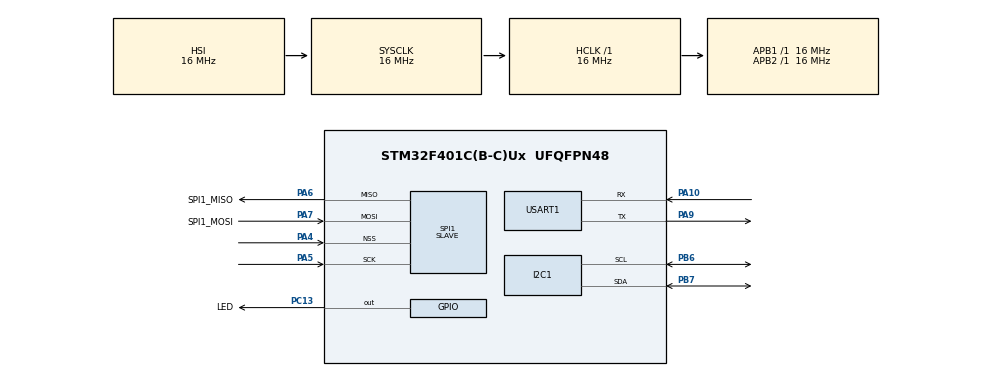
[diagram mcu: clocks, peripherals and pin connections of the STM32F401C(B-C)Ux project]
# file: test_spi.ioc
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Mcu.Family=STM32F4
Mcu.Name=STM32F401C(B-C)Ux
Mcu.Package=UFQFPN48
NVIC.PriorityGroup=NVIC_PRIORITYGROUP_4
NVIC.SPI1_IRQn=true\:0\:0\:false\:false\:true\:true\:true\:true
NVIC.TIM2_IRQn=true\:0\:0\:false\:false\:true\:true\:true\:true
NVIC.USART1_IRQn=true\:0\:0\:false\:false\:true\:true\:true\:true
PA10.Mode=Asynchronous
PA10.Signal=USART1_RX
PA4.Mode=NSS_Signal_Hard_Input
PA4.Signal=SPI1_NSS
PA5.Mode=Full_Duplex_Slave
PA5.Signal=SPI1_SCK
PA6.GPIO_Label=SPI1_MISO
PA6.Mode=Full_Duplex_Slave
PA6.Signal=SPI1_MISO
PA7.GPIO_Label=SPI1_MOSI
PA7.Mode=Full_Duplex_Slave
PA7.Signal=SPI1_MOSI
PA9.Mode=Asynchronous
PA9.Signal=USART1_TX
PB6.Mode=I2C
PB6.Signal=I2C1_SCL
PB7.Mode=I2C
PB7.Signal=I2C1_SDA
PC13-ANTI_TAMP.GPIO_Label=LED
PC13-ANTI_TAMP.GPIO_ModeDefaultOutputPP=GPIO_MODE_OUTPUT_PP
PC13-ANTI_TAMP.GPIO_PuPd=GPIO_NOPULL
PC13-ANTI_TAMP.Signal=GPIO_Output
PH0\ -\ OSC_IN.Mode=HSE-External-Oscillator
PH0\ -\ OSC_IN.Signal=RCC_OSC_IN
PH1\ -\ OSC_OUT.Mode=HSE-External-Oscillator
PH1\ -\ OSC_OUT.Signal=RCC_OSC_OUT
ProjectManager.HeapSize=0x200
ProjectManager.StackSize=0x400
ProjectManager.TargetToolchain=STM32CubeIDE
RCC.AHBFreq_Value=16000000
RCC.APB1Freq_Value=16000000
RCC.APB2Freq_Value=16000000
RCC.CortexFreq_Value=16000000
RCC.HSE_VALUE=25000000
RCC.HSI_VALUE=16000000
RCC.LSE_VALUE=32768
RCC.SYSCLKFreq_VALUE=16000000
RCC.VCOOutputFreq_Value=192000000
SPI1.CLKPhase=SPI_PHASE_1EDGE
SPI1.CLKPolarity=SPI_POLARITY_LOW
SPI1.CRCCalculation=SPI_CRCCALCULATION_DISABLE
SPI1.Direction=SPI_DIRECTION_2LINES
SPI1.FirstBit=SPI_FIRSTBIT_MSB
SPI1.Mode=SPI_MODE_SLAVE
SPI1.VirtualNSS=VM_NSSHARD
SPI1.VirtualType=VM_SLAVE
TIM2.AutoReloadPreload=TIM_AUTORELOAD_PRELOAD_ENABLE
TIM2.Period=16000
TIM2.Prescaler=1000
USART1.Parity=PARITY_ODD
USART1.VirtualMode=VM_ASYNC
USART1.WordLength=WORDLENGTH_9B
VP_TIM2_VS_ClockSourceINT.Mode=Internal
board=custom

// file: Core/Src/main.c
/* USER CODE BEGIN Header */
/**
  ******************************************************************************
  * @file           : main.c
  * @brief          : Main program body
  ******************************************************************************
  * @attention
  *
  * Copyright (c) 2022 STMicroelectronics.
  * All rights reserved.
  *
  * This software is licensed under terms that can be found in the LICENSE file
  * in the root directory of this software component.
  * If no LICENSE file comes with this software, it is provided AS-IS.
  *
  ******************************************************************************
  */
/* USER CODE END Header */
#include "main.h"

/* USER CODE BEGIN Includes */
#include "maincode.h"
/* USER CODE END Includes */

 I2C_HandleTypeDef hi2c1;

SPI_HandleTypeDef hspi1;

TIM_HandleTypeDef htim2;

UART_HandleTypeDef huart1;

void SystemClock_Config(void);
static void MX_GPIO_Init(void);
static void MX_SPI1_Init(void);
static void MX_USART1_UART_Init(void);
static void MX_I2C1_Init(void);
static void MX_TIM2_Init(void);

int main(void)
{

  /* MCU Configuration--------------------------------------------------------*/

  /* Reset of all peripherals, Initializes the Flash interface and the Systick. */
  HAL_Init();

  /* Configure the system clock */
  SystemClock_Config();

  /* Initialize all configured peripherals */
  MX_GPIO_Init();
  MX_SPI1_Init();
  MX_USART1_UART_Init();
  MX_I2C1_Init();
  MX_TIM2_Init();
  /* USER CODE BEGIN 2 */
  HAL_GPIO_WritePin(LED_GPIO_Port, LED_Pin, 1);
  lcd_start();
  HAL_TIM_Base_Start_IT(&htim2);
  /* USER CODE END 2 */

  /* Infinite loop */
  while (1)
  {

    /* USER CODE BEGIN 3 */
	mainloop();
  }
  /* USER CODE END 3 */
}

void SystemClock_Config(void)
{
  RCC_OscInitTypeDef RCC_OscInitStruct = {0};
  RCC_ClkInitTypeDef RCC_ClkInitStruct = {0};

  /** Configure the main internal regulator output voltage
  */
  __HAL_RCC_PWR_CLK_ENABLE();
  __HAL_PWR_VOLTAGESCALING_CONFIG(PWR_REGULATOR_VOLTAGE_SCALE2);

  /** Initializes the RCC Oscillators according to the specified parameters
  * in the RCC_OscInitTypeDef structure.
  */
  RCC_OscInitStruct.OscillatorType = RCC_OSCILLATORTYPE_HSI;
  RCC_OscInitStruct.HSIState = RCC_HSI_ON;
  RCC_OscInitStruct.HSICalibrationValue = RCC_HSICALIBRATION_DEFAULT;
  RCC_OscInitStruct.PLL.PLLState = RCC_PLL_NONE;
  if (HAL_RCC_OscConfig(&RCC_OscInitStruct) != HAL_OK)
  {
    Error_Handler();
  }

  /** Initializes the CPU, AHB and APB buses clocks
  */
  RCC_ClkInitStruct.ClockType = RCC_CLOCKTYPE_HCLK|RCC_CLOCKTYPE_SYSCLK
                              |RCC_CLOCKTYPE_PCLK1|RCC_CLOCKTYPE_PCLK2;
  RCC_ClkInitStruct.SYSCLKSource = RCC_SYSCLKSOURCE_HSI;
  RCC_ClkInitStruct.AHBCLKDivider = RCC_SYSCLK_DIV1;
  RCC_ClkInitStruct.APB1CLKDivider = RCC_HCLK_DIV1;
  RCC_ClkInitStruct.APB2CLKDivider = RCC_HCLK_DIV1;

  if (HAL_RCC_ClockConfig(&RCC_ClkInitStruct, FLASH_LATENCY_0) != HAL_OK)
  {
    Error_Handler();
  }
}

static void MX_I2C1_Init(void)
{

  hi2c1.Instance = I2C1;
  hi2c1.Init.ClockSpeed = 100000;
  hi2c1.Init.DutyCycle = I2C_DUTYCYCLE_2;
  hi2c1.Init.OwnAddress1 = 0;
  hi2c1.Init.AddressingMode = I2C_ADDRESSINGMODE_7BIT;
  hi2c1.Init.DualAddressMode = I2C_DUALADDRESS_DISABLE;
  hi2c1.Init.OwnAddress2 = 0;
  hi2c1.Init.GeneralCallMode = I2C_GENERALCALL_DISABLE;
  hi2c1.Init.NoStretchMode = I2C_NOSTRETCH_DISABLE;
  if (HAL_I2C_Init(&hi2c1) != HAL_OK)
  {
    Error_Handler();
  }

}

static void MX_SPI1_Init(void)
{

  /* SPI1 parameter configuration*/
  hspi1.Instance = SPI1;
  hspi1.Init.Mode = SPI_MODE_SLAVE;
  hspi1.Init.Direction = SPI_DIRECTION_2LINES;
  hspi1.Init.DataSize = SPI_DATASIZE_8BIT;
  hspi1.Init.CLKPolarity = SPI_POLARITY_LOW;
  hspi1.Init.CLKPhase = SPI_PHASE_1EDGE;
  hspi1.Init.NSS = SPI_NSS_HARD_INPUT;
  hspi1.Init.FirstBit = SPI_FIRSTBIT_MSB;
  hspi1.Init.TIMode = SPI_TIMODE_DISABLE;
  hspi1.Init.CRCCalculation = SPI_CRCCALCULATION_DISABLE;
  hspi1.Init.CRCPolynomial = 10;
  if (HAL_SPI_Init(&hspi1) != HAL_OK)
  {
    Error_Handler();
  }
  /* USER CODE BEGIN SPI1_Init 2 */
  NVIC_SetPriority(SPI1_IRQn, NVIC_EncodePriority(NVIC_GetPriorityGrouping(), 0, 0));
  NVIC_EnableIRQ(SPI1_IRQn);
  /* USER CODE END SPI1_Init 2 */

}

static void MX_TIM2_Init(void)
{

  TIM_ClockConfigTypeDef sClockSourceConfig = {0};
  TIM_MasterConfigTypeDef sMasterConfig = {0};

  htim2.Instance = TIM2;
  htim2.Init.Prescaler = 1000;
  htim2.Init.CounterMode = TIM_COUNTERMODE_UP;
  htim2.Init.Period = 16000;
  htim2.Init.ClockDivision = TIM_CLOCKDIVISION_DIV1;
  htim2.Init.AutoReloadPreload = TIM_AUTORELOAD_PRELOAD_ENABLE;
  if (HAL_TIM_Base_Init(&htim2) != HAL_OK)
  {
    Error_Handler();
  }
  sClockSourceConfig.ClockSource = TIM_CLOCKSOURCE_INTERNAL;
  if (HAL_TIM_ConfigClockSource(&htim2, &sClockSourceConfig) != HAL_OK)
  {
    Error_Handler();
  }
  sMasterConfig.MasterOutputTrigger = TIM_TRGO_RESET;
  sMasterConfig.MasterSlaveMode = TIM_MASTERSLAVEMODE_DISABLE;
  if (HAL_TIMEx_MasterConfigSynchronization(&htim2, &sMasterConfig) != HAL_OK)
  {
    Error_Handler();
  }

}

static void MX_USART1_UART_Init(void)
{

  huart1.Instance = USART1;
  huart1.Init.BaudRate = 115200;
  huart1.Init.WordLength = UART_WORDLENGTH_9B;
  huart1.Init.StopBits = UART_STOPBITS_1;
  huart1.Init.Parity = UART_PARITY_ODD;
  huart1.Init.Mode = UART_MODE_TX_RX;
  huart1.Init.HwFlowCtl = UART_HWCONTROL_NONE;
  huart1.Init.OverSampling = UART_OVERSAMPLING_16;
  if (HAL_UART_Init(&huart1) != HAL_OK)
  {
    Error_Handler();
  }
  /* USER CODE BEGIN USART1_Init 2 */
  NVIC_SetPriority(USART1_IRQn, NVIC_EncodePriority(NVIC_GetPriorityGrouping(), 0, 0));
  NVIC_EnableIRQ(USART1_IRQn);
  /* USER CODE END USART1_Init 2 */

}

static void MX_GPIO_Init(void)
{
  GPIO_InitTypeDef GPIO_InitStruct = {0};

  /* GPIO Ports Clock Enable */
  __HAL_RCC_GPIOC_CLK_ENABLE();
  __HAL_RCC_GPIOH_CLK_ENABLE();
  __HAL_RCC_GPIOA_CLK_ENABLE();
  __HAL_RCC_GPIOB_CLK_ENABLE();

  /*Configure GPIO pin Output Level */
  HAL_GPIO_WritePin(LED_GPIO_Port, LED_Pin, GPIO_PIN_RESET);

  /*Configure GPIO pin : LED_Pin */
  GPIO_InitStruct.Pin = LED_Pin;
  GPIO_InitStruct.Mode = GPIO_MODE_OUTPUT_PP;
  GPIO_InitStruct.Pull = GPIO_NOPULL;
  GPIO_InitStruct.Speed = GPIO_SPEED_FREQ_LOW;
  HAL_GPIO_Init(LED_GPIO_Port, &GPIO_InitStruct);

}

void Error_Handler(void)
{
  __disable_irq();
  while (1)
  {
  }
}
